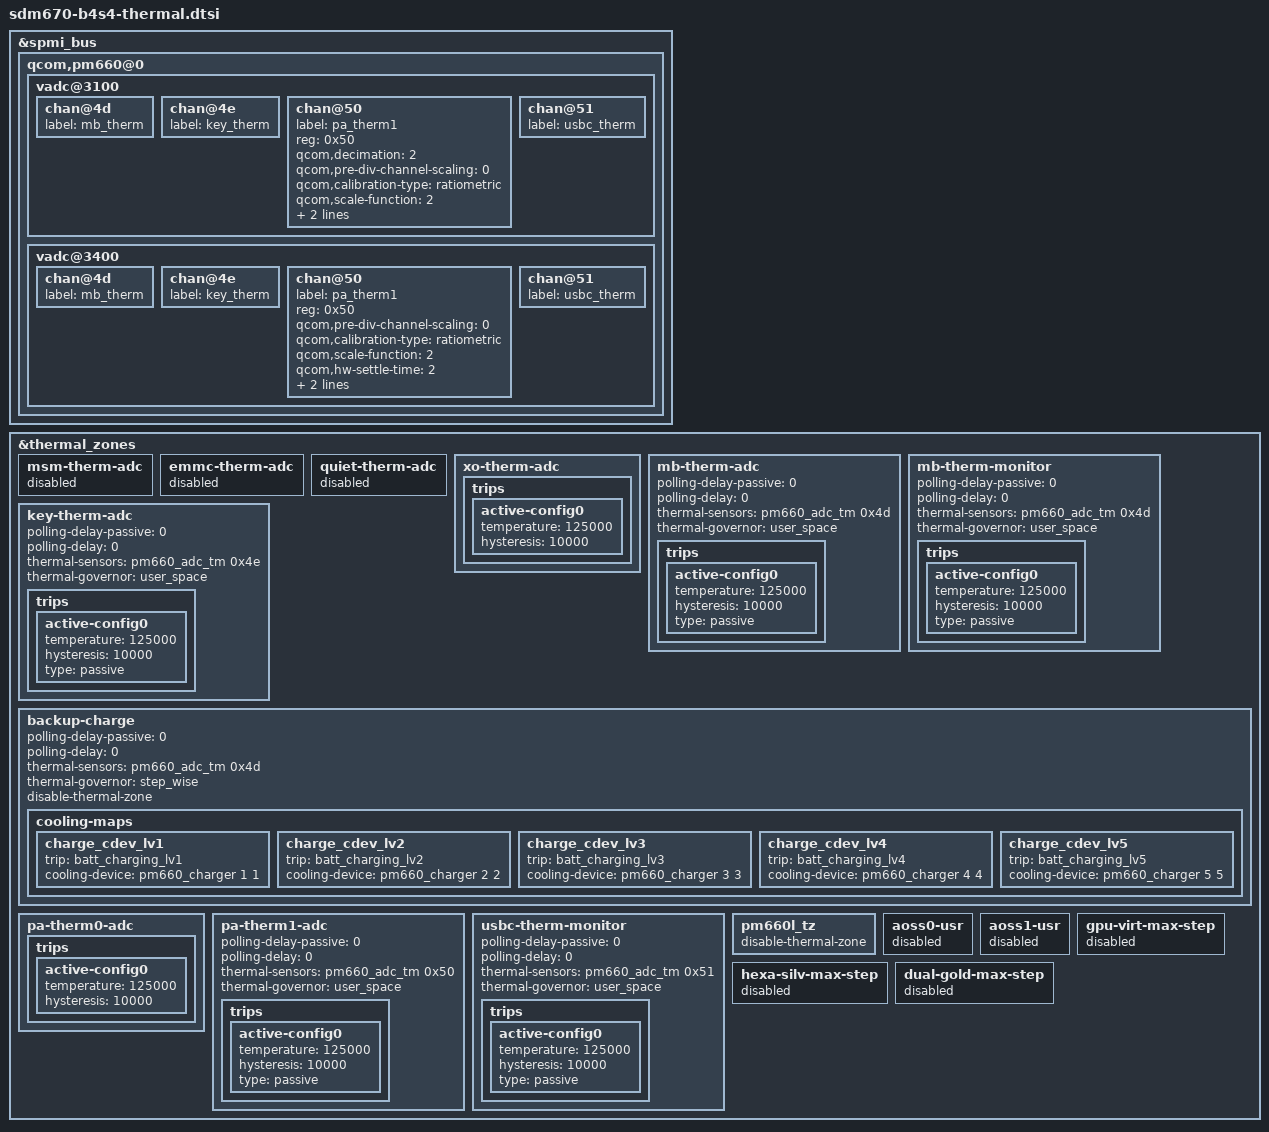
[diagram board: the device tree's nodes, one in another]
/* Copyright (c) 2018, The Linux Foundation. All rights reserved.
 *
 * This program is free software; you can redistribute it and/or modify
 * it under the terms of the GNU General Public License version 2 and
 * only version 2 as published by the Free Software Foundation.
 *
 * This program is distributed in the hope that it will be useful,
 * but WITHOUT ANY WARRANTY; without even the implied warranty of
 * MERCHANTABILITY or FITNESS FOR A PARTICULAR PURPOSE.  See the
 * GNU General Public License for more details.
 */

/* sdm670-b4s4-common.dtsi includes go here */

/*
 * Rename msm_therm to mb_therm.
 * Rename emmc_therm to key_therm.
 * Rename quiet_therm to usbc_therm.
 * Register pa_therm1 thermistor.
 */
&spmi_bus {
	qcom,pm660@0 {
		vadc@3100 {
			chan@4d {
				label = "mb_therm";
			};

			chan@4e {
				label = "key_therm";
			};

			chan@50 {
				label = "pa_therm1";
				reg = <0x50>;
				qcom,decimation = <2>;
				qcom,pre-div-channel-scaling = <0>;
				qcom,calibration-type = "ratiometric";
				qcom,scale-function = <2>;
				qcom,hw-settle-time = <2>;
				qcom,fast-avg-setup = <0>;
			};

			chan@51 {
				label = "usbc_therm";
			};
		};

		vadc@3400 {
			chan@4d {
				label = "mb_therm";
			};

			chan@4e {
				label = "key_therm";
			};

			chan@50 {
				label = "pa_therm1";
				reg = <0x50>;
				qcom,pre-div-channel-scaling = <0>;
				qcom,calibration-type = "ratiometric";
				qcom,scale-function = <2>;
				qcom,hw-settle-time = <2>;
				qcom,btm-channel-number = <0x90>;
				qcom,thermal-node;
			};

			chan@51 {
				label = "usbc_therm";
			};
		};
	};
};


/*
 * Rename msm-therm-adc to mb-therm-adc.
 * Rename emmc-therm-adc to key-therm-adc.
 * Rename quiet-therm-adc to usbc-therm-monitor.
 * Register pa_therm1 thermal_zone.
 */
&thermal_zones {
	msm-therm-adc {
		status = "disabled";
	};

	emmc-therm-adc {
		status = "disabled";
	};

	quiet-therm-adc {
		status = "disabled";
	};

	xo-therm-adc {
		trips {
			active-config0 {
				temperature = <125000>;
				hysteresis = <10000>;
			};
		};
	};

	mb-therm-adc {
		polling-delay-passive = <0>;
		polling-delay = <0>;
		thermal-sensors = <&pm660_adc_tm 0x4d>;
		thermal-governor = "user_space";

		trips {
			active-config0 {
				temperature = <125000>;
				hysteresis = <10000>;
				type = "passive";
			};
		};
	};

	mb-therm-monitor {
		polling-delay-passive = <0>;
		polling-delay = <0>;
		thermal-sensors = <&pm660_adc_tm 0x4d>;
		thermal-governor = "user_space";

		trips {
			active-config0 {
				temperature = <125000>;
				hysteresis = <10000>;
				type = "passive";
			};
		};
	};

	key-therm-adc {
		polling-delay-passive = <0>;
		polling-delay = <0>;
		thermal-sensors = <&pm660_adc_tm 0x4e>;
		thermal-governor = "user_space";

		trips {
			active-config0 {
				temperature = <125000>;
				hysteresis = <10000>;
				type = "passive";
			};
		};
	};

	backup-charge {
		polling-delay-passive = <0>;
		polling-delay = <0>;
		thermal-sensors = <&pm660_adc_tm 0x4d>;
		thermal-governor = "step_wise";
		disable-thermal-zone;

		cooling-maps {
			charge_cdev_lv1 {
				trip = <&batt_charging_lv1>;
				cooling-device = <&pm660_charger 1 1>;
			};
			charge_cdev_lv2 {
				trip = <&batt_charging_lv2>;
				cooling-device = <&pm660_charger 2 2>;
			};
			charge_cdev_lv3 {
				trip = <&batt_charging_lv3>;
				cooling-device = <&pm660_charger 3 3>;
			};
			charge_cdev_lv4 {
				trip = <&batt_charging_lv4>;
				cooling-device = <&pm660_charger 4 4>;
			};
			charge_cdev_lv5 {
				trip = <&batt_charging_lv5>;
				cooling-device = <&pm660_charger 5 5>;
			};
		};
	};

	pa-therm0-adc {
		trips {
			active-config0 {
				temperature = <125000>;
				hysteresis = <10000>;
			};
		};
	};

	pa-therm1-adc {
		polling-delay-passive = <0>;
		polling-delay = <0>;
		thermal-sensors = <&pm660_adc_tm 0x50>;
		thermal-governor = "user_space";

		trips {
			active-config0 {
				temperature = <125000>;
				hysteresis = <10000>;
				type = "passive";
			};
		};
	};

	usbc-therm-monitor {
		polling-delay-passive = <0>;
		polling-delay = <0>;
		thermal-sensors = <&pm660_adc_tm 0x51>;
		thermal-governor = "user_space";

		trips {
			active-config0 {
				temperature = <125000>;
				hysteresis = <10000>;
				type = "passive";
			};
		};
	};

	pm660l_tz {
		disable-thermal-zone;
	};

	aoss0-usr {
		status = "disabled";
	};

	aoss1-usr {
		status = "disabled";
	};

	gpu-virt-max-step {
		status = "disabled";
	};

	hexa-silv-max-step {
		status = "disabled";
	};

	dual-gold-max-step {
		status = "disabled";
	};
};
